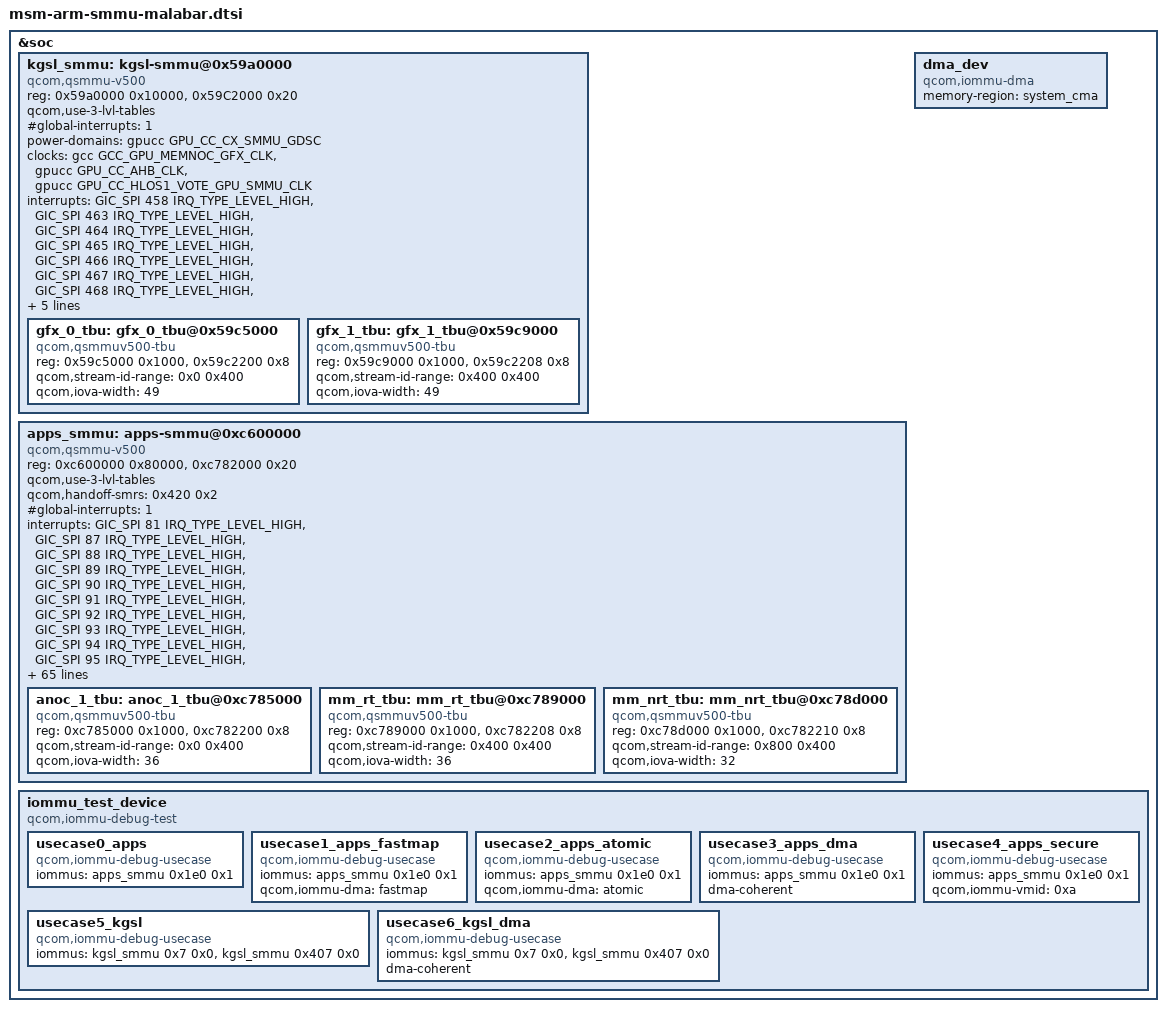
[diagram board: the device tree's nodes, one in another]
// SPDX-License-Identifier: BSD-3-Clause
/*
 * Copyright (c) Qualcomm Technologies, Inc. and/or its subsidiaries.
 */

#include <dt-bindings/interrupt-controller/arm-gic.h>

&soc {
	kgsl_smmu: kgsl-smmu@0x59a0000 {
		compatible = "qcom,qsmmu-v500", "qcom,adreno-smmu";
		reg = <0x59a0000 0x10000>,
			<0x59C2000 0x20>;
		reg-names = "base", "tcu-base";
		#iommu-cells = <2>;
		qcom,use-3-lvl-tables;
		#global-interrupts = <1>;
		#size-cells = <1>;
		#address-cells = <1>;
		ranges;

		power-domains = <&gpucc GPU_CC_CX_SMMU_GDSC>;

		clocks = <&gcc GCC_GPU_MEMNOC_GFX_CLK>,
			 <&gpucc GPU_CC_AHB_CLK>,
			 <&gpucc GPU_CC_HLOS1_VOTE_GPU_SMMU_CLK>;
		clock-names = "gcc_gpu_memnoc_gfx",
			      "gpu_cc_ahb",
			      "gpu_cc_hlos1_vote_gpu_smmu_clk";

		interrupts =	<GIC_SPI 458 IRQ_TYPE_LEVEL_HIGH>,
				<GIC_SPI 463 IRQ_TYPE_LEVEL_HIGH>,
				<GIC_SPI 464 IRQ_TYPE_LEVEL_HIGH>,
				<GIC_SPI 465 IRQ_TYPE_LEVEL_HIGH>,
				<GIC_SPI 466 IRQ_TYPE_LEVEL_HIGH>,
				<GIC_SPI 467 IRQ_TYPE_LEVEL_HIGH>,
				<GIC_SPI 468 IRQ_TYPE_LEVEL_HIGH>,
				<GIC_SPI 469 IRQ_TYPE_LEVEL_HIGH>,
				<GIC_SPI 470 IRQ_TYPE_LEVEL_HIGH>;

		qcom,actlr =
			/* GPU */
			<0x0000 0x0401 0x0000032b>,
			<0x0002 0x0400 0x0000032b>,
			<0x0007 0x0400 0x0000032b>;

		gfx_0_tbu: gfx_0_tbu@0x59c5000 {
			compatible = "qcom,qsmmuv500-tbu";
			reg = <0x59c5000 0x1000>,
				<0x59c2200 0x8>;
			reg-names = "base", "status-reg";
			qcom,stream-id-range = <0x0 0x400>;
			qcom,iova-width = <49>;
		};

		gfx_1_tbu: gfx_1_tbu@0x59c9000 {
			compatible = "qcom,qsmmuv500-tbu";
			reg = <0x59c9000 0x1000>,
				<0x59c2208 0x8>;
			reg-names = "base", "status-reg";
			qcom,stream-id-range = <0x400 0x400>;
			qcom,iova-width = <49>;
		};

	};

	apps_smmu: apps-smmu@0xc600000 {
		compatible = "qcom,qsmmu-v500";
		reg = <0xc600000 0x80000>,
			<0xc782000 0x20>;
		reg-names = "base", "tcu-base";
		#iommu-cells = <2>;
		qcom,use-3-lvl-tables;
		qcom,handoff-smrs = <0x420 0x2>;
		#global-interrupts = <1>;
		#size-cells = <1>;
		#address-cells = <1>;
		ranges;

		interrupts =	<GIC_SPI 81 IRQ_TYPE_LEVEL_HIGH>,
				<GIC_SPI 87 IRQ_TYPE_LEVEL_HIGH>,
				<GIC_SPI 88 IRQ_TYPE_LEVEL_HIGH>,
				<GIC_SPI 89 IRQ_TYPE_LEVEL_HIGH>,
				<GIC_SPI 90 IRQ_TYPE_LEVEL_HIGH>,
				<GIC_SPI 91 IRQ_TYPE_LEVEL_HIGH>,
				<GIC_SPI 92 IRQ_TYPE_LEVEL_HIGH>,
				<GIC_SPI 93 IRQ_TYPE_LEVEL_HIGH>,
				<GIC_SPI 94 IRQ_TYPE_LEVEL_HIGH>,
				<GIC_SPI 95 IRQ_TYPE_LEVEL_HIGH>,
				<GIC_SPI 96 IRQ_TYPE_LEVEL_HIGH>,
				<GIC_SPI 97 IRQ_TYPE_LEVEL_HIGH>,
				<GIC_SPI 98 IRQ_TYPE_LEVEL_HIGH>,
				<GIC_SPI 99 IRQ_TYPE_LEVEL_HIGH>,
				<GIC_SPI 100 IRQ_TYPE_LEVEL_HIGH>,
				<GIC_SPI 101 IRQ_TYPE_LEVEL_HIGH>,
				<GIC_SPI 102 IRQ_TYPE_LEVEL_HIGH>,
				<GIC_SPI 103 IRQ_TYPE_LEVEL_HIGH>,
				<GIC_SPI 104 IRQ_TYPE_LEVEL_HIGH>,
				<GIC_SPI 105 IRQ_TYPE_LEVEL_HIGH>,
				<GIC_SPI 106 IRQ_TYPE_LEVEL_HIGH>,
				<GIC_SPI 107 IRQ_TYPE_LEVEL_HIGH>,
				<GIC_SPI 108 IRQ_TYPE_LEVEL_HIGH>,
				<GIC_SPI 109 IRQ_TYPE_LEVEL_HIGH>,
				<GIC_SPI 110 IRQ_TYPE_LEVEL_HIGH>,
				<GIC_SPI 111 IRQ_TYPE_LEVEL_HIGH>,
				<GIC_SPI 112 IRQ_TYPE_LEVEL_HIGH>,
				<GIC_SPI 113 IRQ_TYPE_LEVEL_HIGH>,
				<GIC_SPI 114 IRQ_TYPE_LEVEL_HIGH>,
				<GIC_SPI 115 IRQ_TYPE_LEVEL_HIGH>,
				<GIC_SPI 116 IRQ_TYPE_LEVEL_HIGH>,
				<GIC_SPI 117 IRQ_TYPE_LEVEL_HIGH>,
				<GIC_SPI 118 IRQ_TYPE_LEVEL_HIGH>,
				<GIC_SPI 119 IRQ_TYPE_LEVEL_HIGH>,
				<GIC_SPI 120 IRQ_TYPE_LEVEL_HIGH>,
				<GIC_SPI 121 IRQ_TYPE_LEVEL_HIGH>,
				<GIC_SPI 122 IRQ_TYPE_LEVEL_HIGH>,
				<GIC_SPI 123 IRQ_TYPE_LEVEL_HIGH>,
				<GIC_SPI 124 IRQ_TYPE_LEVEL_HIGH>,
				<GIC_SPI 125 IRQ_TYPE_LEVEL_HIGH>,
				<GIC_SPI 126 IRQ_TYPE_LEVEL_HIGH>,
				<GIC_SPI 127 IRQ_TYPE_LEVEL_HIGH>,
				<GIC_SPI 128 IRQ_TYPE_LEVEL_HIGH>,
				<GIC_SPI 129 IRQ_TYPE_LEVEL_HIGH>,
				<GIC_SPI 130 IRQ_TYPE_LEVEL_HIGH>,
				<GIC_SPI 131 IRQ_TYPE_LEVEL_HIGH>,
				<GIC_SPI 132 IRQ_TYPE_LEVEL_HIGH>,
				<GIC_SPI 133 IRQ_TYPE_LEVEL_HIGH>,
				<GIC_SPI 134 IRQ_TYPE_LEVEL_HIGH>,
				<GIC_SPI 135 IRQ_TYPE_LEVEL_HIGH>,
				<GIC_SPI 136 IRQ_TYPE_LEVEL_HIGH>,
				<GIC_SPI 137 IRQ_TYPE_LEVEL_HIGH>,
				<GIC_SPI 138 IRQ_TYPE_LEVEL_HIGH>,
				<GIC_SPI 139 IRQ_TYPE_LEVEL_HIGH>,
				<GIC_SPI 140 IRQ_TYPE_LEVEL_HIGH>,
				<GIC_SPI 141 IRQ_TYPE_LEVEL_HIGH>,
				<GIC_SPI 142 IRQ_TYPE_LEVEL_HIGH>,
				<GIC_SPI 143 IRQ_TYPE_LEVEL_HIGH>,
				<GIC_SPI 144 IRQ_TYPE_LEVEL_HIGH>,
				<GIC_SPI 145 IRQ_TYPE_LEVEL_HIGH>,
				<GIC_SPI 146 IRQ_TYPE_LEVEL_HIGH>,
				<GIC_SPI 147 IRQ_TYPE_LEVEL_HIGH>,
				<GIC_SPI 148 IRQ_TYPE_LEVEL_HIGH>,
				<GIC_SPI 149 IRQ_TYPE_LEVEL_HIGH>,
				<GIC_SPI 150 IRQ_TYPE_LEVEL_HIGH>;

		qcom,actlr =
			/* Camera */
			<0x0400 0x0000 0x00000103>,
			<0x0800 0x0000 0x00000103>,
			<0x0820 0x0000 0x00000103>,
			<0x0840 0x0000 0x00000103>,

			/* Display */
			<0x0420 0x0002 0x00000103>,
			<0x0421 0x0000 0x00000103>,

			/* Video */
			<0x0980 0x0020 0x00000103>,
			<0x0981 0x0004 0x00000103>,
			<0x0983 0x0000 0x00000103>,
			<0x0984 0x0020 0x00000103>;

		anoc_1_tbu: anoc_1_tbu@0xc785000 {
			compatible = "qcom,qsmmuv500-tbu";
			reg = <0xc785000 0x1000>,
				<0xc782200 0x8>;
			reg-names = "base", "status-reg";
			qcom,stream-id-range = <0x0 0x400>;
			qcom,iova-width = <36>;
		};

		mm_rt_tbu: mm_rt_tbu@0xc789000 {
			compatible = "qcom,qsmmuv500-tbu";
			reg = <0xc789000 0x1000>,
				<0xc782208 0x8>;
			reg-names = "base", "status-reg";
			qcom,stream-id-range = <0x400 0x400>;
			qcom,iova-width = <36>;
		};

		mm_nrt_tbu: mm_nrt_tbu@0xc78d000 {
			compatible = "qcom,qsmmuv500-tbu";
			reg = <0xc78d000 0x1000>,
				<0xc782210 0x8>;
			reg-names = "base", "status-reg";
			qcom,stream-id-range = <0x800 0x400>;
			qcom,iova-width = <32>;
		};

	};

	dma_dev {
		compatible = "qcom,iommu-dma";
		memory-region = <&system_cma>;
	};

	iommu_test_device {
		compatible = "qcom,iommu-debug-test";

		usecase0_apps {
			compatible = "qcom,iommu-debug-usecase";
			iommus = <&apps_smmu 0x1e0 0x1>;
		};

		usecase1_apps_fastmap {
			compatible = "qcom,iommu-debug-usecase";
			iommus = <&apps_smmu 0x1e0 0x1>;
			qcom,iommu-dma = "fastmap";
		};

		usecase2_apps_atomic {
			compatible = "qcom,iommu-debug-usecase";
			iommus = <&apps_smmu 0x1e0 0x1>;
			qcom,iommu-dma = "atomic";
		};

		usecase3_apps_dma {
			compatible = "qcom,iommu-debug-usecase";
			iommus = <&apps_smmu 0x1e0 0x1>;
			dma-coherent;
		};

		usecase4_apps_secure {
			compatible = "qcom,iommu-debug-usecase";
			iommus = <&apps_smmu 0x1e0 0x1>;
			qcom,iommu-vmid = <0xa>; /* VMID_CP_PIXEL */
		};

		usecase5_kgsl {
			compatible = "qcom,iommu-debug-usecase";
			iommus = <&kgsl_smmu 0x7 0x0>, <&kgsl_smmu 0x407 0x0>;
		};

		usecase6_kgsl_dma {
			compatible = "qcom,iommu-debug-usecase";
			iommus = <&kgsl_smmu 0x7 0x0>, <&kgsl_smmu 0x407 0x0>;
			dma-coherent;
		};
	};
};
